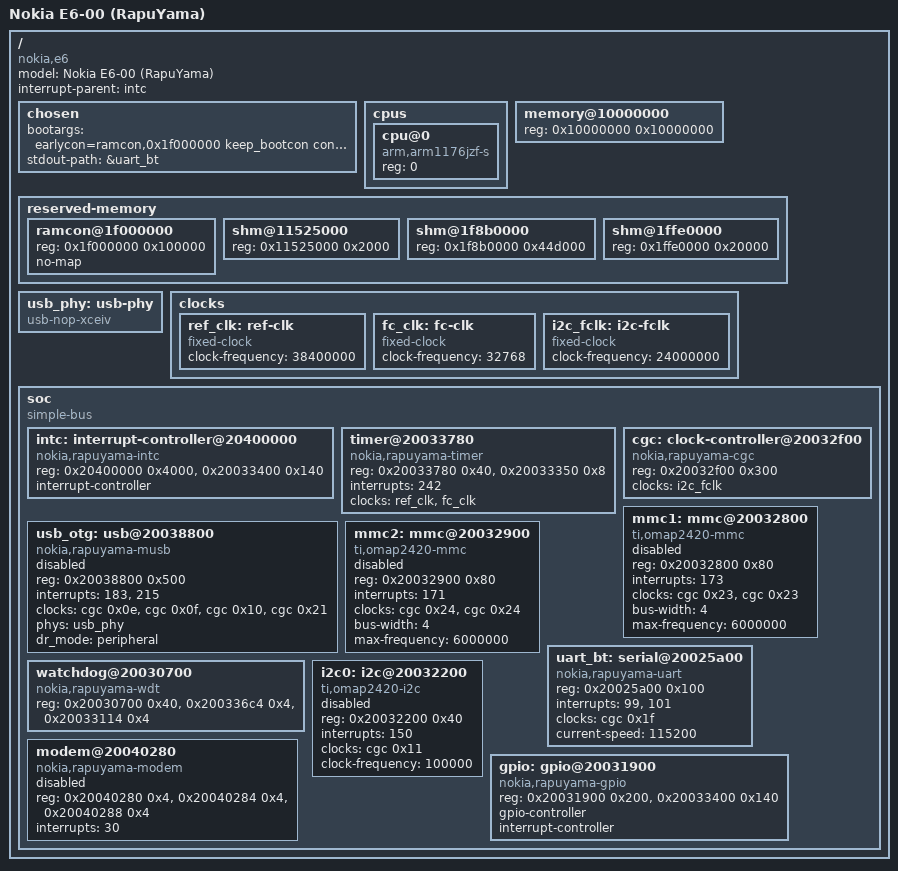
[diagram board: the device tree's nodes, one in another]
/dts-v1/;

/* device tree for the nokia e6 (rapuyama, arm1176jzf-s r0p4, armv6k)
 *
 * peripheral addresses + register layouts are reversed from the firmware
 * drivers (karap/ekern/power.dll), see docs/driver-re.md. ram ends at
 * 0x20000000, everything from there up is mmio, NOT reserved dram like i thought
 * before. The booter leaves this fixed RAM range unchanged; the kernel is
 * configured with PHYS_OFFSET=0x10000000 to match it.
 */

/ {
	compatible = "nokia,e6", "nokia,rapuyama";
	model = "Nokia E6-00 (RapuYama)";
	#address-cells = <1>;
	#size-cells = <1>;
	interrupt-parent = <&intc>;

	chosen {
		/* console = the bluetooth uart over the N8 test pads J6354 (our tx)
		 * / J6355 (our rx), 1.8 V! switch bluetooth on in symbian first so
		 * the block is powered/clocked/muxed. panic=10 + the pmic watchdog
		 * bring the phone back to symbian if it dies */
		bootargs = "earlycon=ramcon,0x1f000000 keep_bootcon console=ttyNULL panic=10 initcall_debug ignore_loglevel nohlt";
		stdout-path = &uart_bt;
	};

	cpus {
		#address-cells = <1>;
		#size-cells = <0>;
		cpu@0 {
			device_type = "cpu";
			compatible = "arm,arm1176jzf-s";
			reg = <0>;
		};
	};

	/* all 256 mb: symbian is dead after the jump. The kernel is linked with
	 * PHYS_OFFSET=0x10000000 and the decompressor writes the Image at
	 * 0x10008000, regardless of where the booter allocated the source chunk. */
	memory@10000000 {
		device_type = "memory";
		reg = <0x10000000 0x10000000>;
	};

	/* RAM earlycon buffer (earlycon=ramcon,0x1f000000). linux writes all printk
	 * here from the very start of setup_arch; survives the warm watchdog reset;
	 * driver/ramread.sis reads it back. reserved so the allocator keeps off it */
	reserved-memory {
		#address-cells = <1>;
		#size-cells = <1>;
		ranges;

		ramcon@1f000000 {
			reg = <0x1f000000 0x100000>;
			no-map;
		};

		/* ram symbian maps in its 0xc6 hw window next to the mmio (unfiltered
		 * sweep, logs/map (3).bin), so it's shared with something that isn't
		 * the arm: modem / secure side (power.dll + secldd use 0x1ffe8000 and
		 * 0x1ffec000). that something can keep writing after the jump, and
		 * linux used to put its first allocations right there (memblock
		 * hands out the top of ram first: vectors page, page tables). keep
		 * off them. mach-rapuyama watches them and logs any page that changes.
		 * NOT no-map: a no-map hole at the top of ram / off a 2 mb boundary
		 * makes arm (no highmem) drop all ram above 0x11400000 -> oom */
		shm@11525000 {
			reg = <0x11525000 0x2000>;
		};

		shm@1f8b0000 {
			reg = <0x1f8b0000 0x44d000>;
		};

		shm@1ffe0000 {
			reg = <0x1ffe0000 0x20000>;
		};
	};

	/* ULPI phy inside the Gazoo asic, symbian leaves it set up */
	usb_phy: usb-phy {
		compatible = "usb-nop-xceiv";
		#phy-cells = <0>;
	};

	clocks {
		/* 0x0249f000 all over the firmware */
		ref_clk: ref-clk {
			compatible = "fixed-clock";
			#clock-cells = <0>;
			clock-frequency = <38400000>;
		};
		/* NKern::FastCounterFrequency() returns 0x8000 */
		fc_clk: fc-clk {
			compatible = "fixed-clock";
			#clock-cells = <0>;
			clock-frequency = <32768>;
		};
		/* i2c functional clock, measured live 13.10 (regprobe): pll 192 mhz
		 * (0x20032644 = 0x1e2) / 8 (0x20033010 sel 4) = 24 mhz */
		i2c_fclk: i2c-fclk {
			compatible = "fixed-clock";
			#clock-cells = <0>;
			clock-frequency = <24000000>;
		};
	};

	soc {
		compatible = "simple-bus";
		#address-cells = <1>;
		#size-cells = <1>;
		ranges;

		/* karap irq/fiq dispatchers + Interrupt:: code, 421 lines */
		intc: interrupt-controller@20400000 {
			compatible = "nokia,rapuyama-intc";
			/* main bank + the 5 gpio/periph secondary banks (0x20033400) */
			reg = <0x20400000 0x4000>, <0x20033400 0x140>;
			interrupt-controller;
			#interrupt-cells = <1>;
		};

		/* ms timer (BindMsTick, irq 242) + free running 32k counter (NKern::FastCounter) */
		timer@20033780 {
			compatible = "nokia,rapuyama-timer";
			reg = <0x20033780 0x40>, <0x20033350 0x8>;
			interrupts = <242>;
			clocks = <&ref_clk>, <&fc_clk>;
			clock-names = "ref", "fc";
		};

		/* clock gates from power_resources.dll, index = PowerResourceManager
		 * resource id (0x11 = EHwClkI2C1 for i2c, 0x1f = BT uart clock), each
		 * one turns on its hw gates. all hang off the i2c fclk for now (only
		 * i2c uses a rate). 0x11 + 0x1f are critical = always on, symbian gates
		 * them when idle and touching those blocks with the clock off kills
		 * the phone (regprobe runs 1+2) */
		cgc: clock-controller@20032f00 {
			compatible = "nokia,rapuyama-cgc";
			reg = <0x20032f00 0x300>;
			clocks = <&i2c_fclk>;
			#clock-cells = <1>;
		};

		/* usb.dll: Mentor MUSB + TI OMAP2430 style otg wrapper at +0x400,
		 * ULPI phy in the Gazoo asic (left as symbian set it up). irq 183 =
		 * core, 215 = dma. off by default, e6-usb.dts turns it on */
		usb_otg: usb@20038800 {
			compatible = "nokia,rapuyama-musb";
			reg = <0x20038800 0x500>;
			interrupts = <183>, <215>;
			interrupt-names = "mc", "dma";
			/* EHwClkDomHSUSB (power domain + gates), EHwClkHSUSB, and
			 * EHwClkI2C0 + EHwClkDspSpi1, which usb.dll also asks for */
			clocks = <&cgc 0x0e>, <&cgc 0x0f>, <&cgc 0x10>, <&cgc 0x21>;
			phys = <&usb_phy>;
			dr_mode = "peripheral";
			status = "disabled";
		};

		/* EPBUSMV.DLL: two TI OMAP1/2420 style mmc controllers, tables at
		 * 0x80164558 (base 0/0x100), 0x80164568 (irq 0xad/0xab), 0x80164578
		 * (power resource 0x23/0x24 = direct gates). N8 schematic: microSD
		 * on MMC2. fclk rate unknown (gates hang off the 24 mhz i2c clock
		 * here), so max-frequency is kept low. off until tested */
		mmc1: mmc@20032800 {
			compatible = "ti,omap2420-mmc";
			reg = <0x20032800 0x80>;
			interrupts = <173>;
			clocks = <&cgc 0x23>, <&cgc 0x23>;
			clock-names = "ick", "fck";
			bus-width = <4>;
			max-frequency = <6000000>;
			status = "disabled";
		};

		mmc2: mmc@20032900 {
			compatible = "ti,omap2420-mmc";
			reg = <0x20032900 0x80>;
			interrupts = <171>;
			clocks = <&cgc 0x24>, <&cgc 0x24>;
			clock-names = "ick", "fck";
			bus-width = <4>;
			max-frequency = <6000000>;
			status = "disabled";
		};

		/* bc02_uart1.PDD, the uart to the bluetooth chip (earlycon only) */
		uart_bt: serial@20025a00 {
			compatible = "nokia,rapuyama-uart";
			reg = <0x20025a00 0x100>;
			interrupts = <99>, <101>;
			clocks = <&cgc 0x1f>;
			current-speed = <115200>;
		};

		/* pmic watchdog over the cbus master + soc counter, symbian left both
		 * running. 3rd reg = soc reset (rebootdriver.ldd: write 2) */
		watchdog@20030700 {
			compatible = "nokia,rapuyama-wdt";
			reg = <0x20030700 0x40>, <0x200336c4 0x4>, <0x20033114 0x4>;
		};

		/* modem IRQ/status registers from karap.dll. off while the random
		 * deaths are bisected: these writes go to the modem side and the
		 * phone died with both versions, one variable at a time */
		modem@20040280 {
			compatible = "nokia,rapuyama-modem";
			reg = <0x20040280 0x4>, <0x20040284 0x4>, <0x20040288 0x4>;
			interrupts = <30>;
			status = "disabled";
		};

		/* i2c0.dll: same regs, bits and scl formula as the TI OMAP i2c
		 * (omap2420 layout, 16 bit regs 4 apart). irq 0x96. LM8320 keypad
		 * controller (keypad_exp.dll) hangs on i2c */
		i2c0: i2c@20032200 {
			compatible = "ti,omap2420-i2c";
			reg = <0x20032200 0x40>;
			interrupts = <150>;
			clocks = <&cgc 0x11>;
			clock-names = "fck";
			clock-frequency = <100000>;
			/* off for the first boots: regprobe run 3 died on OA (+0x28) and
			 * i2c-omap pokes regs like that at probe */
			status = "disabled";
			#address-cells = <1>;
			#size-cells = <0>;
		};

		/* egpio.dll, 5 in/out banks + 2 output only banks. second reg =
		 * pin irq enable/ack/trigger banks, each pin has its own intc line */
		gpio: gpio@20031900 {
			compatible = "nokia,rapuyama-gpio";
			reg = <0x20031900 0x200>, <0x20033400 0x140>;
			gpio-controller;
			#gpio-cells = <2>;
			interrupt-controller;
			#interrupt-cells = <2>;
		};
	};
};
